# QEMU_RISCV_VIRT register map
Vendor: qemu.org; Series: RISC-V; File version: 0.1
CPU: riscv r0p0, little endian, no MPU, no FPU, 0 interrupt priority bits
Registers are 32-bit, read-write, reset 0x0 unless marked. A register's access mark holds for its fields unless they carry their own. Offsets are from the block's base; [hi:lo] are bit positions; lines under a group give offsets from that group; {n}, {i} and the like mark numbered series.

## I2C0 — ODP socket-backed I2C controller
Base 0x10001000
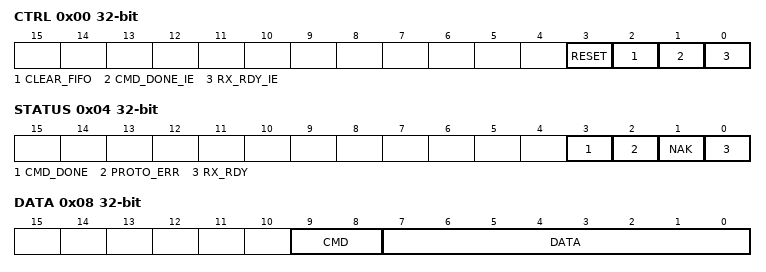
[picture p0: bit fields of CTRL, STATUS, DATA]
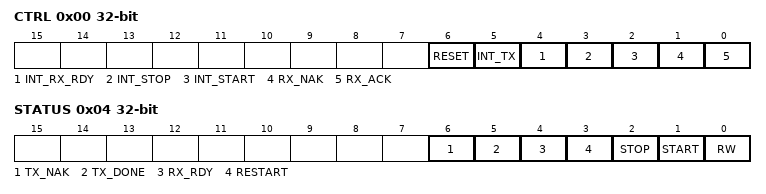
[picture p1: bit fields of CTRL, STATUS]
0x00 CTRL — Control register
  [3] RESET write-1-sets — Soft reset (write-1, self-clearing)
  [2] CLEAR_FIFO write-1-clears — Clear RX FIFO (write-1, self-clearing)
  [1] CMD_DONE_IE — Command-complete interrupt enable
  [0] RX_RDY_IE — RX-ready interrupt enable
0x04 STATUS
  [3] CMD_DONE write-1-clears — Command completed (write-1-to-clear)
  [2] PROTO_ERR write-1-clears — Illegal command ordering (write-1-to-clear)
  [1] NAK write-1-clears — Target NAKed / link dropped (write-1-to-clear)
  [0] RX_RDY ro — RX FIFO not empty
0x08 DATA — Data register: read pops RX FIFO; write issues a command
  [9:8] CMD — Command on write (0=START, 1=STOP, 2=RX, 3=TX)
  [7:0] DATA — Data byte (RX byte on read, TX/address byte on write)

## I2C_TARGET — ODP socket-backed I2C target
Base 0x10002000
0x00 CTRL — Control register
  [6] RESET write-1-sets — Recover / soft reset (write-1, self-clearing)
  [5] INT_TX — Interrupt enable: TX done
  [4] INT_RX_RDY — Interrupt enable: byte received
  [3] INT_STOP — Interrupt enable: STOP
  [2] INT_START — Interrupt enable: addressed (START)
  [1] RX_NAK write-1-sets — NAK pending RX byte / reject (write-1 strobe)
  [0] RX_ACK write-1-sets — ACK pending RX byte and continue (write-1 strobe)
0x04 STATUS
  [6] TX_NAK ro — Last TX byte: 1=controller NAKed (done)
  [5] TX_DONE write-1-clears — TX byte clocked and controller replied (write-1-to-clear)
  [4] RX_RDY ro — Byte in DATA awaiting strobe
  [3] RESTART write-1-clears — Repeated START, also sets START (write-1-to-clear)
  [2] STOP write-1-clears — Controller sent STOP (write-1-to-clear)
  [1] START write-1-clears — Addressed: address matched (write-1-to-clear)
  [0] RW ro — Transfer direction (1=controller read, 0=controller write)
0x08 ADDR — Target match address
  [6:0] ADDR — 7-bit address this target answers to
0x0C DATA — Data register: RX byte on read, TX byte on write
  [7:0] DATA — Data byte

## GPIO — ODP socket-backed bidirectional GPIO controller (32 pins, one bit per pin)
Base 0x10003000
0x00 IN ro — Input level (one bit per pin, driven by each pin's peer)
  [31:0] IN — Per-pin input level
0x04 OUT — Output level (one bit per pin, driven to each pin's peer)
  [31:0] OUT — Per-pin output level
0x08 IRQ_TRIG — Interrupt trigger type (0 = level, 1 = edge)
  [31:0] IRQ_TRIG — Per-pin trigger select (0 = level, 1 = edge)
0x0C IRQ_POL — Interrupt polarity (0 = low/falling, 1 = high/rising)
  [31:0] IRQ_POL — Per-pin polarity select (0 = low/falling, 1 = high/rising)
0x10 IRQ_EN — Per-pin interrupt enable
0x14 IRQ_PEND — Per-pin interrupt pending (write-1-to-clear)
  [31:0] IRQ_PEND write-1-clears

## ESPI_TARGET — ODP socket-backed eSPI target. Registers require aligned 32-bit accesses. Host addresses are independent of the EC mailbox memory windows.
Base 0x10004000
0x00 CONTROL — Enable peripheral-channel mailbox access. Program all three decode bases while disabled; enabling requires distinct, 4-KiB-aligned bases.
  [0] ENABLE — Enable host access to mailbox data and control windows
0x04 MAILBOX0_ADDR — Mailbox zero host decode base, not an EC pointer. Must be 4-KiB aligned and distinct from the other bases. Change only while CONTROL.ENABLE is zero.
0x08 MAILBOX1_ADDR — Mailbox one host decode base, not an EC pointer. Must be 4-KiB aligned and distinct from the other bases. Change only while CONTROL.ENABLE is zero.
0x0C CONTROL_ADDR — Host control-window decode base, not an EC pointer. Must be 4-KiB aligned and distinct from the mailbox bases. Change only while CONTROL.ENABLE is zero.
{0x10+0xC*i} MAILBOX_CONTROL[{i}] (i=0..1) group — EC mailbox-control registers with 0x0c stride. Host control groups use 0x20 stride and expose IRQ acknowledgement instead of IRQ set.
  0x00 SHARED_STATUS — Application-defined shared status, writable by EC and host
  0x04 DOORBELL write-1-clears — Host-to-EC doorbell pending. EC writes bit zero as one to clear; pending doorbells assert PLIC source 5.
    [0] PENDING
  0x08 IRQ_SET write-1-sets — Read host IRQ pending; write one to assert host IRQ
    [0] PENDING

## ESPI_MAILBOX0 — Fixed 4-KiB EC view of eSPI mailbox zero RAM. The host decode base does not relocate this window. Supports aligned 8-, 16- and 32-bit accesses; data accesses do not ring the doorbell.
Base 0x10005000
Same registers: ESPI_MAILBOX1 0x10006000
{0x0+i} DATA[{i}] (i=0..4095) 8-bit — Shared mailbox byte; the host may update memory independently of the EC
